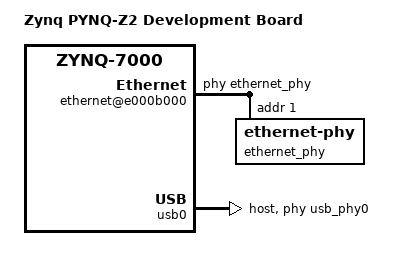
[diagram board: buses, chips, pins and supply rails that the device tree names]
/dts-v1/;

#include "system-top.dts"

/ {
	model = "Zynq PYNQ-Z2 Development Board";
	compatible = "digilent,zynq-artyz", "xlnx,zynq-7000";

	chosen {
		bootargs = "earlycon root=/dev/mmcblk0p2 rw rootfstype=ext4 rootwait";
		stdout-path = "serial0:115200n8";
	};

	amba {
		ethernet@e000b000 {
			phy-handle = <&ethernet_phy>;
			ethernet_phy: ethernet-phy@1{
				reg = <1>;
			};
		};
	};

        usb_phy0: phy0 {
                compatible = "ulpi-phy";
                #phy-cells = <0>;
                reg = <0xe0002000 0x1000>;
                view-port = <0x170>;
                drv-vbus;
        };
};

&usb0 {
	dr_mode = "host";
        usb-phy = <&usb_phy0>;
};
